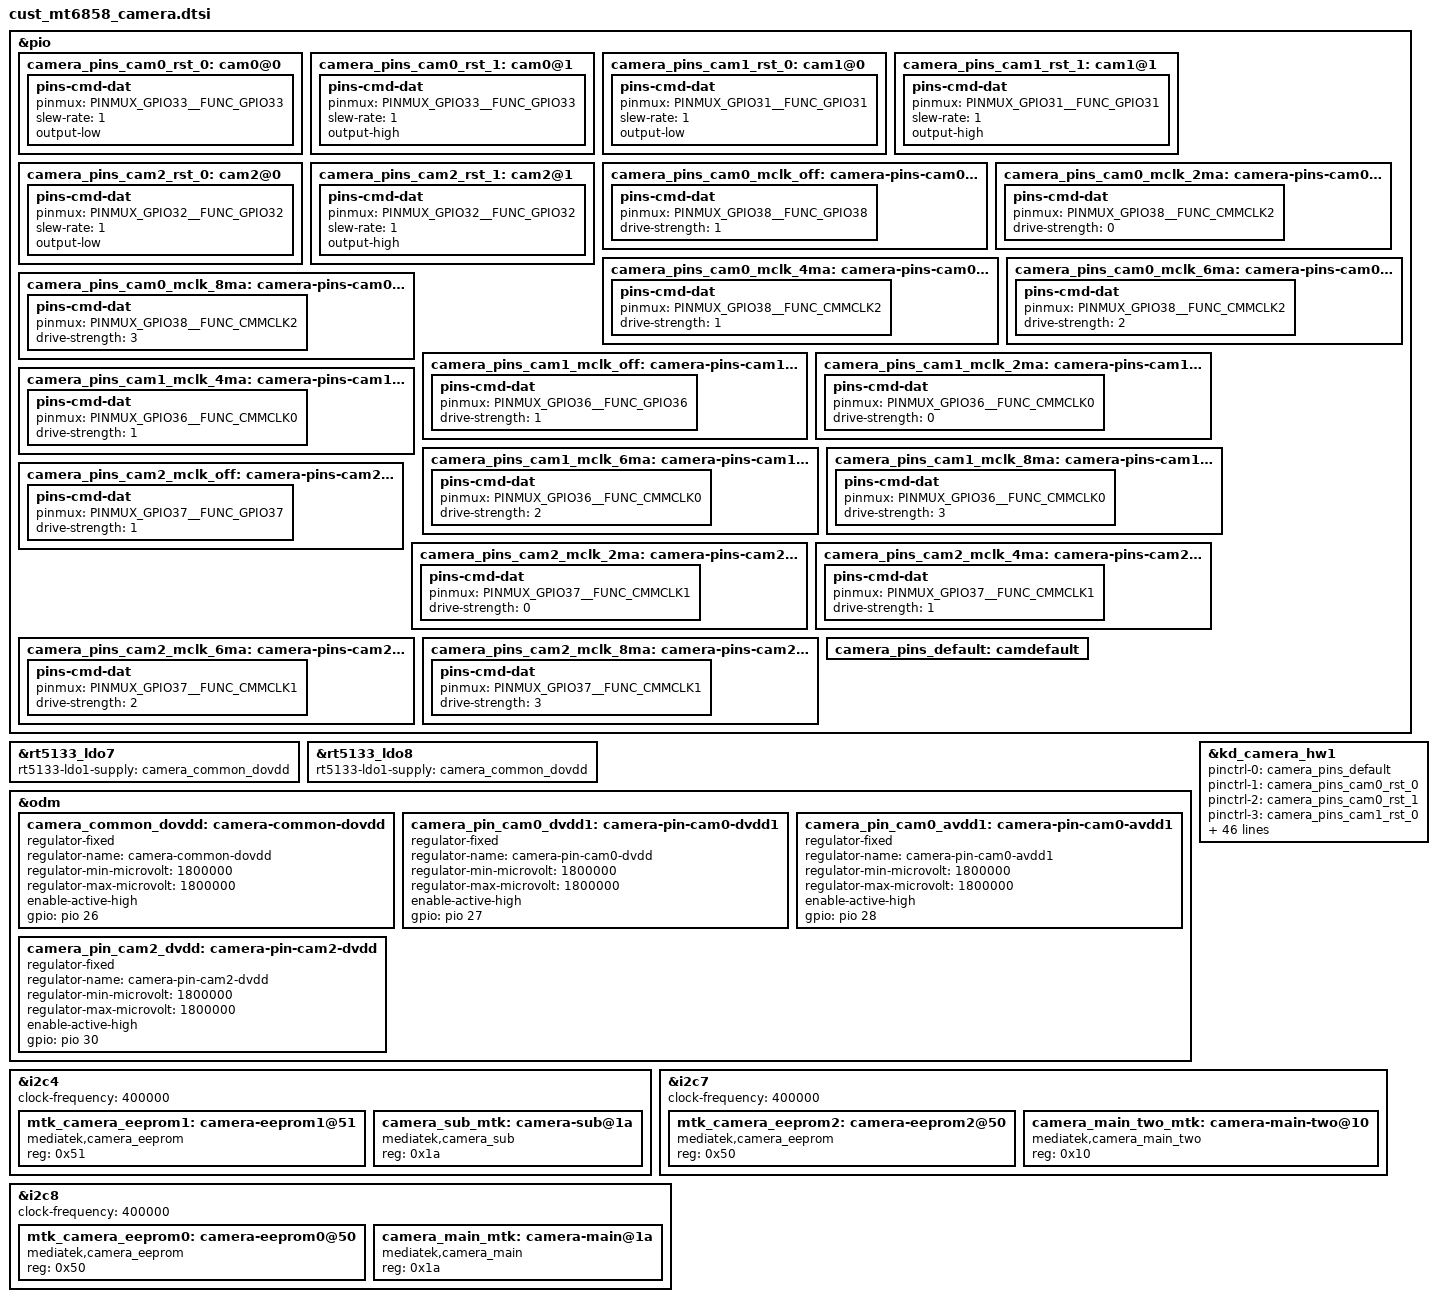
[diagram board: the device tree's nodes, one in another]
// SPDX-License-Identifier: GPL-2.0
/* Copyright (c) 2025 MediaTek Inc. */
/* CAMERA GPIO standardization */
&pio {
	camera_pins_cam0_rst_0: cam0@0 {
		pins-cmd-dat {
			pinmux = <PINMUX_GPIO33__FUNC_GPIO33>;
			slew-rate = <1>;
			output-low;
		};
	};
	camera_pins_cam0_rst_1: cam0@1 {
		pins-cmd-dat {
			pinmux = <PINMUX_GPIO33__FUNC_GPIO33>;
			slew-rate = <1>;
			output-high;
		};
	};
	camera_pins_cam1_rst_0: cam1@0 {
		pins-cmd-dat {
			pinmux = <PINMUX_GPIO31__FUNC_GPIO31>;
			slew-rate = <1>;
			output-low;
		};
	};
	camera_pins_cam1_rst_1: cam1@1 {
		pins-cmd-dat {
			pinmux = <PINMUX_GPIO31__FUNC_GPIO31>;
			slew-rate = <1>;
			output-high;
		};
	};
	camera_pins_cam2_rst_0: cam2@0 {
		pins-cmd-dat {
			pinmux = <PINMUX_GPIO32__FUNC_GPIO32>;
			slew-rate = <1>;
			output-low;
		};
	};
	camera_pins_cam2_rst_1: cam2@1 {
		pins-cmd-dat {
			pinmux = <PINMUX_GPIO32__FUNC_GPIO32>;
			slew-rate = <1>;
			output-high;
		};
	};
	camera_pins_cam0_mclk_off: camera-pins-cam0-mclk-off {
		pins-cmd-dat {
			pinmux = <PINMUX_GPIO38__FUNC_GPIO38>;
			drive-strength = <1>;
		};
	};
	camera_pins_cam0_mclk_2ma: camera-pins-cam0-mclk-2ma {
		pins-cmd-dat {
			pinmux = <PINMUX_GPIO38__FUNC_CMMCLK2>;
			drive-strength = <0>;
		};
	};
	camera_pins_cam0_mclk_4ma: camera-pins-cam0-mclk-4ma {
		pins-cmd-dat {
			pinmux = <PINMUX_GPIO38__FUNC_CMMCLK2>;
			drive-strength = <1>;
		};
	};
	camera_pins_cam0_mclk_6ma: camera-pins-cam0-mclk-6ma {
		pins-cmd-dat {
			pinmux = <PINMUX_GPIO38__FUNC_CMMCLK2>;
			drive-strength = <2>;
		};
	};
	camera_pins_cam0_mclk_8ma: camera-pins-cam0-mclk-8ma {
		pins-cmd-dat {
			pinmux = <PINMUX_GPIO38__FUNC_CMMCLK2>;
			drive-strength = <3>;
		};
	};
	camera_pins_cam1_mclk_off: camera-pins-cam1-mclk-off {
		pins-cmd-dat {
			pinmux = <PINMUX_GPIO36__FUNC_GPIO36>;
			drive-strength = <1>;
		};
	};
	camera_pins_cam1_mclk_2ma: camera-pins-cam1-mclk-2ma {
		pins-cmd-dat {
			pinmux = <PINMUX_GPIO36__FUNC_CMMCLK0>;
			drive-strength = <0>;
		};
	};
	camera_pins_cam1_mclk_4ma: camera-pins-cam1-mclk-4ma {
		pins-cmd-dat {
			pinmux = <PINMUX_GPIO36__FUNC_CMMCLK0>;
			drive-strength = <1>;
		};
	};
	camera_pins_cam1_mclk_6ma: camera-pins-cam1-mclk-6ma {
		pins-cmd-dat {
			pinmux = <PINMUX_GPIO36__FUNC_CMMCLK0>;
			drive-strength = <2>;
		};
	};
	camera_pins_cam1_mclk_8ma: camera-pins-cam1-mclk-8ma {
		pins-cmd-dat {
			pinmux = <PINMUX_GPIO36__FUNC_CMMCLK0>;
			drive-strength = <3>;
		};
	};
	camera_pins_cam2_mclk_off: camera-pins-cam2-mclk-off {
		pins-cmd-dat {
			pinmux = <PINMUX_GPIO37__FUNC_GPIO37>;
			drive-strength = <1>;
		};
	};
	camera_pins_cam2_mclk_2ma: camera-pins-cam2-mclk-2ma {
		pins-cmd-dat {
			pinmux = <PINMUX_GPIO37__FUNC_CMMCLK1>;
			drive-strength = <0>;
		};
	};
	camera_pins_cam2_mclk_4ma: camera-pins-cam2-mclk-4ma {
		pins-cmd-dat {
			pinmux = <PINMUX_GPIO37__FUNC_CMMCLK1>;
			drive-strength = <1>;
		};
	};
	camera_pins_cam2_mclk_6ma: camera-pins-cam2-mclk-6ma {
		pins-cmd-dat {
			pinmux = <PINMUX_GPIO37__FUNC_CMMCLK1>;
			drive-strength = <2>;
		};
	};
	camera_pins_cam2_mclk_8ma: camera-pins-cam2-mclk-8ma {
		pins-cmd-dat {
			pinmux = <PINMUX_GPIO37__FUNC_CMMCLK1>;
			drive-strength = <3>;
		};
	};
	camera_pins_default: camdefault {
	};
};
&rt5133_ldo7 {
	rt5133-ldo1-supply = <&camera_common_dovdd>;
};

&rt5133_ldo8 {
	rt5133-ldo1-supply = <&camera_common_dovdd>;
};
&odm {
	camera_common_dovdd: camera-common-dovdd {
		compatible = "regulator-fixed";
		regulator-name = "camera-common-dovdd";
		regulator-min-microvolt = <1800000>;
		regulator-max-microvolt = <1800000>;
		enable-active-high;
		gpio = <&pio 26 0x0>;
	};
	camera_pin_cam0_dvdd1:camera-pin-cam0-dvdd1 {
		compatible = "regulator-fixed";
		regulator-name = "camera-pin-cam0-dvdd";
		regulator-min-microvolt = <1800000>;
		regulator-max-microvolt = <1800000>;
		enable-active-high;
		gpio = <&pio 27 0x0>;
	};
	camera_pin_cam0_avdd1:camera-pin-cam0-avdd1 {
		compatible = "regulator-fixed";
		regulator-name = "camera-pin-cam0-avdd1";
		regulator-min-microvolt = <1800000>;
		regulator-max-microvolt = <1800000>;
		enable-active-high;
		gpio = <&pio 28 0x0>;
	};
	camera_pin_cam2_dvdd:camera-pin-cam2-dvdd {
		compatible = "regulator-fixed";
		regulator-name = "camera-pin-cam2-dvdd";
		regulator-min-microvolt = <1800000>;
		regulator-max-microvolt = <1800000>;
		enable-active-high;
		gpio = <&pio 30 0x0>;
	};
};
&kd_camera_hw1 {
	pinctrl-names = "default",
			"cam0_rst0", "cam0_rst1",
			"cam1_rst0", "cam1_rst1",
			"cam2_rst0", "cam2_rst1",
			"cam0_mclk_off",
			"cam0_mclk_2mA", "cam0_mclk_4mA",
			"cam0_mclk_6mA", "cam0_mclk_8mA",
			"cam1_mclk_off",
			"cam1_mclk_2mA", "cam1_mclk_4mA",
			"cam1_mclk_6mA", "cam1_mclk_8mA",
			"cam2_mclk_off",
			"cam2_mclk_2mA", "cam2_mclk_4mA",
			"cam2_mclk_6mA", "cam2_mclk_8mA";
	pinctrl-0 = <&camera_pins_default>;
	pinctrl-1 = <&camera_pins_cam0_rst_0>;
	pinctrl-2 = <&camera_pins_cam0_rst_1>;
	pinctrl-3 = <&camera_pins_cam1_rst_0>;
	pinctrl-4 = <&camera_pins_cam1_rst_1>;
	pinctrl-5 = <&camera_pins_cam2_rst_0>;
	pinctrl-6 = <&camera_pins_cam2_rst_1>;
	pinctrl-7 = <&camera_pins_cam0_mclk_off>;
	pinctrl-8 = <&camera_pins_cam0_mclk_2ma>;
	pinctrl-9 = <&camera_pins_cam0_mclk_4ma>;
	pinctrl-10 = <&camera_pins_cam0_mclk_6ma>;
	pinctrl-11 = <&camera_pins_cam0_mclk_8ma>;
	pinctrl-12 = <&camera_pins_cam1_mclk_off>;
	pinctrl-13 = <&camera_pins_cam1_mclk_2ma>;
	pinctrl-14 = <&camera_pins_cam1_mclk_4ma>;
	pinctrl-15 = <&camera_pins_cam1_mclk_6ma>;
	pinctrl-16 = <&camera_pins_cam1_mclk_8ma>;
	pinctrl-17 = <&camera_pins_cam2_mclk_off>;
	pinctrl-18 = <&camera_pins_cam2_mclk_2ma>;
	pinctrl-19 = <&camera_pins_cam2_mclk_4ma>;
	pinctrl-20 = <&camera_pins_cam2_mclk_6ma>;
	pinctrl-21 = <&camera_pins_cam2_mclk_8ma>;

	/* main (wide) */
	cam0_vcama-supply = <&rt5133_ldo5>;
	cam0_vcama1-supply = <&camera_pin_cam0_avdd1>;
	cam0_vcamd-supply = <&rt5133_ldo7>;
	cam0_vcamd1-supply = <&camera_pin_cam0_dvdd1>;
	cam0_vcamio-supply = <&camera_common_dovdd>;

	/* front */
	cam1_vcama-supply = <&rt5133_ldo3>;
	cam1_vcamd-supply = <&rt5133_gpio3>;
	cam1_vcamio-supply = <&camera_common_dovdd>;

	/* main2 (tele) */
	cam2_vcama-supply = <&rt5133_ldo3>;
	cam2_vcamd-supply = <&camera_pin_cam2_dvdd>;
	cam2_vcamio-supply = <&camera_common_dovdd>;

	cam0_pin_mclk = "mclk";
	cam0_pin_rst = "gpio";
	cam0_pin_vcama = "regulator";
	cam0_pin_vcama1 = "regulator";
	cam0_pin_vcamd = "regulator";
	cam0_pin_vcamd1 = "regulator";
	cam0_pin_vcamio = "regulator";
	cam1_pin_mclk = "mclk";
	cam1_pin_rst = "gpio";
	cam1_pin_vcama = "regulator";
	cam1_pin_vcamd = "regulator";
	cam1_pin_vcamio = "regulator";
	cam2_pin_mclk = "mclk";
	cam2_pin_rst = "gpio";
	cam2_pin_vcama = "regulator";
	cam2_pin_vcamd = "regulator";
	cam2_pin_vcamio = "regulator";

	status = "okay";
};
/* CAMERA GPIO end */

/* CAMERA EEPROM */
&i2c4 {
	status = "okay";
	clock-frequency = <400000>;
	#address-cells = <1>;
	#size-cells = <0>;
	mtk_camera_eeprom1:camera-eeprom1@51 {
		compatible = "mediatek,camera_eeprom";
		reg = <0x51>;
		status = "okay";
	};
	camera_sub_mtk:camera-sub@1a {
		compatible = "mediatek,camera_sub";
		#thermal-sensor-cells = <0>;
		reg = <0x1a>;
		status = "okay";
	};
};
&i2c7 {
	status = "okay";
	clock-frequency = <400000>;
	#address-cells = <1>;
	#size-cells = <0>;

	mtk_camera_eeprom2:camera-eeprom2@50 {
		compatible = "mediatek,camera_eeprom";
		reg = <0x50>;
		status = "okay";
	};
	camera_main_two_mtk:camera-main-two@10 {
		compatible = "mediatek,camera_main_two";
		#thermal-sensor-cells = <0>;
		reg = <0x10>;
		status = "okay";
	};
};
&i2c8 {
	status = "okay";
	clock-frequency = <400000>;
	#address-cells = <1>;
	#size-cells = <0>;
	mtk_camera_eeprom0:camera-eeprom0@50 {
		compatible = "mediatek,camera_eeprom";
		reg = <0x50>;
		status = "okay";
	};
	camera_main_mtk:camera-main@1a {
		compatible = "mediatek,camera_main";
		#thermal-sensor-cells = <0>;
		reg = <0x1a>;
		status = "okay";
	};
};
/* CAMERA EEPROM end */

/* CAMERA TZ config */
#if 0  /* temp disable thermal node */
&thermal_zones {
	camera_main: camera-main {
		polling-delay = <1000>; /* milliseconds */
		polling-delay-passive = <0>; /* milliseconds */
		thermal-sensors = <&camera_main_mtk>;
	};
	camera_sub: camera-sub {
		polling-delay = <1000>; /* milliseconds */
		polling-delay-passive = <0>; /* milliseconds */
		thermal-sensors = <&camera_sub_mtk>;
	};
	camera_main_two: camera-main-two {
		polling-delay = <1000>; /* milliseconds */
		polling-delay-passive = <0>; /* milliseconds */
		thermal-sensors = <&camera_main_two_mtk>;
	};
};
#endif


/* CAMERA TZ config end */

/* CAMERA AF */
//&i2c2 {
//	camera_main_two_af_mtk:camera_main_two_af@0c {
//		compatible = "mediatek,camera_main_two_af";
//		reg = <0x0c>;
//		status = "okay";
//	};
//};
//&i2c8 {
//	camera_main_af_mtk:camera_main_af@72 {
//		compatible = "mediatek,camera_main_af";
//		reg = <0x72>;
//		status = "okay";
//	};
//};
//&i2c9 {
//	camera_main_three_af_mtk:camera_main_three_af@0c {
//		compatible = "mediatek,camera_main_three_af";
//		reg = <0x0c>;
//		status = "okay";
//	};
//};
/* CAMERA AF end */
